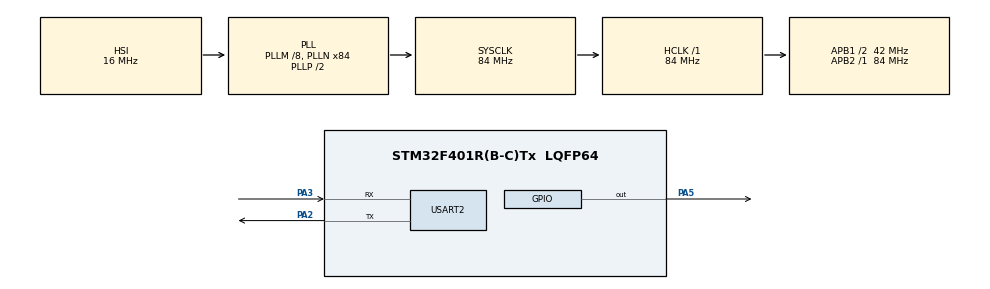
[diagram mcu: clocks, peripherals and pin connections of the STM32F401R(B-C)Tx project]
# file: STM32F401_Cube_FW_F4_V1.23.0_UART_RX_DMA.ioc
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Dma.Request0=USART2_TX
Dma.Request1=USART2_RX
Dma.USART2_RX.1.Direction=DMA_PERIPH_TO_MEMORY
Dma.USART2_RX.1.FIFOMode=DMA_FIFOMODE_DISABLE
Dma.USART2_RX.1.Instance=DMA1_Stream5
Dma.USART2_RX.1.MemDataAlignment=DMA_MDATAALIGN_BYTE
Dma.USART2_RX.1.MemInc=DMA_MINC_ENABLE
Dma.USART2_RX.1.Mode=DMA_CIRCULAR
Dma.USART2_RX.1.PeriphDataAlignment=DMA_PDATAALIGN_BYTE
Dma.USART2_RX.1.PeriphInc=DMA_PINC_DISABLE
Dma.USART2_RX.1.Priority=DMA_PRIORITY_LOW
Dma.USART2_TX.0.Direction=DMA_MEMORY_TO_PERIPH
Dma.USART2_TX.0.FIFOMode=DMA_FIFOMODE_DISABLE
Dma.USART2_TX.0.Instance=DMA1_Stream6
Dma.USART2_TX.0.MemDataAlignment=DMA_MDATAALIGN_BYTE
Dma.USART2_TX.0.MemInc=DMA_MINC_ENABLE
Dma.USART2_TX.0.Mode=DMA_NORMAL
Dma.USART2_TX.0.PeriphDataAlignment=DMA_PDATAALIGN_BYTE
Dma.USART2_TX.0.PeriphInc=DMA_PINC_DISABLE
Dma.USART2_TX.0.Priority=DMA_PRIORITY_LOW
Mcu.Family=STM32F4
Mcu.Name=STM32F401R(B-C)Tx
Mcu.Package=LQFP64
Mcu.UserConstants=SYSCLK,84000000;TIMERCLK,1000000;TIMERFREQ,1000
NVIC.DMA1_Stream5_IRQn=true\:0\:0\:false\:false\:true\:false\:true
NVIC.DMA1_Stream6_IRQn=true\:0\:0\:false\:false\:true\:false\:true
NVIC.PriorityGroup=NVIC_PRIORITYGROUP_4
NVIC.TIM1_TRG_COM_TIM11_IRQn=true\:0\:0\:false\:false\:true\:true\:true
NVIC.USART2_IRQn=true\:0\:0\:false\:false\:true\:true\:true
PA13.Mode=Serial_Wire
PA13.Signal=SYS_JTMS-SWDIO
PA14.Mode=Serial_Wire
PA14.Signal=SYS_JTCK-SWCLK
PA2.Mode=Asynchronous
PA2.Signal=USART2_TX
PA3.Mode=Asynchronous
PA3.Signal=USART2_RX
PA5.Signal=GPIO_Output
ProjectManager.HeapSize=0x200
ProjectManager.StackSize=0x400
ProjectManager.TargetToolchain=MDK-ARM V5
RCC.48MHZClocksFreq_Value=42000000
RCC.AHBFreq_Value=84000000
RCC.APB1CLKDivider=RCC_HCLK_DIV2
RCC.APB1Freq_Value=42000000
RCC.APB1TimFreq_Value=84000000
RCC.APB2Freq_Value=84000000
RCC.APB2TimFreq_Value=84000000
RCC.CortexFreq_Value=84000000
RCC.HCLKFreq_Value=84000000
RCC.HSE_VALUE=25000000
RCC.HSI_VALUE=16000000
RCC.LSE_VALUE=32768
RCC.PLLM=8
RCC.PLLN=84
RCC.SYSCLKFreq_VALUE=84000000
RCC.SYSCLKSource=RCC_SYSCLKSOURCE_PLLCLK
RCC.VCOOutputFreq_Value=168000000
TIM11.Period=TIMERCLK/TIMERFREQ-1
TIM11.Prescaler=SYSCLK/TIMERCLK-1
USART2.VirtualMode=VM_ASYNC
VP_TIM11_VS_ClockSourceINT.Mode=Enable_Timer
board=custom

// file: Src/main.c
/* USER CODE BEGIN Header */
/**
  ******************************************************************************
  * @file           : main.c
  * @brief          : Main program body
  ******************************************************************************
  * @attention
  *
  * <h2><center>&copy; Copyright (c) 2019 STMicroelectronics.
  * All rights reserved.</center></h2>
  *
  * This software component is licensed by ST under BSD 3-Clause license,
  * the "License"; You may not use this file except in compliance with the
  * License. You may obtain a copy of the License at:
  *                        opensource.org/licenses/BSD-3-Clause
  *
  ******************************************************************************
  */
/* USER CODE END Header */

#include "main.h"

/* USER CODE BEGIN PM */
#define RX_DMA_LEN						(256)
#define ARRAY_LEN(x)            			(sizeof(x) / sizeof((x)[0]))

/* USER CODE END PM */

TIM_HandleTypeDef htim11;

UART_HandleTypeDef huart2;
DMA_HandleTypeDef hdma_usart2_tx;
DMA_HandleTypeDef hdma_usart2_rx;

/* USER CODE BEGIN PV */

uint8_t aRxDMABuffer[RX_DMA_LEN] = {0};

/* USER CODE END PV */

void SystemClock_Config(void);
static void MX_GPIO_Init(void);
static void MX_DMA_Init(void);
static void MX_TIM11_Init(void);
static void MX_USART2_UART_Init(void);
/* USER CODE BEGIN PFP */

#ifdef __GNUC__
/* With GCC/RAISONANCE, small printf (option LD Linker->Libraries->Small printf
 set to 'Yes') calls __io_putchar() */
#define PUTCHAR_PROTOTYPE int __io_putchar(int ch)
#else
#define PUTCHAR_PROTOTYPE int fputc(int ch, FILE *f)
#endif /* __GNUC__ */

/**
  * @brief  Retargets the C library printf function to the USART.
  * @param  None
  * @retval None
  */

PUTCHAR_PROTOTYPE
{
	/* Place your implementation of fputc here */
	/* e.g. write a character to the EVAL_COM1 and Loop until the end of transmission */
	HAL_UART_Transmit(&huart2, (uint8_t *)&ch, 1, 0xFFFF);

	return ch;
}

/* USER CODE END PFP */

/* USER CODE BEGIN 0 */

void customIRQ_UART_RxIDLE(void)
{
	//https://github.com/MaJerle/STM32_USART_DMA_RX/blob/master/projects/idle_line_irq_F4/Src/main.c

	static uint16_t OldLength = 0;
	uint16_t RxLength = 0;

	if(__HAL_UART_GET_IT_SOURCE(&huart2, UART_IT_IDLE)  && __HAL_UART_GET_FLAG(&huart2, UART_FLAG_IDLE))
	{
		__HAL_UART_CLEAR_IDLEFLAG(&huart2);

		RxLength = ARRAY_LEN(aRxDMABuffer) - (__HAL_DMA_GET_COUNTER(&hdma_usart2_rx));	//calculate how many data in DMA buffer
//		printf("RX length : 0x%2X \r\n" , RxLength);

		if (RxLength != OldLength)
		{
			if (RxLength > OldLength)
			{
				HAL_UART_Transmit_DMA(&huart2,&aRxDMABuffer[OldLength],RxLength-OldLength);
			}
			else
			{
				HAL_UART_Transmit_DMA(&huart2,&aRxDMABuffer[OldLength],ARRAY_LEN(aRxDMABuffer)-OldLength);
				if (RxLength)
				{
					HAL_UART_Transmit_DMA(&huart2,&aRxDMABuffer[0],RxLength);
				}
			}
		}

		OldLength = (OldLength == ARRAY_LEN(aRxDMABuffer))?(0):(RxLength);
	}
}

void HAL_TIM_PeriodElapsedCallback(TIM_HandleTypeDef *htim)
{
	static uint32_t cnt1 = 0;
	static uint32_t i = 0;

	if (htim->Instance == TIM11)
	{
		if (cnt1++ >= (1*1000))	// per 1 s
		{
			cnt1 = 0;
			printf("%s : %4d\r\n",__FUNCTION__,i++);

		}
	}
}

/* USER CODE END 0 */

int main(void)
{

  /* MCU Configuration--------------------------------------------------------*/

  /* Reset of all peripherals, Initializes the Flash interface and the Systick. */
  HAL_Init();

  /* Configure the system clock */
  SystemClock_Config();

  /* Initialize all configured peripherals */
  MX_GPIO_Init();
  MX_DMA_Init();
  MX_TIM11_Init();
  MX_USART2_UART_Init();

  /* Infinite loop */
  while (1)
  {

    /* USER CODE BEGIN 3 */

	HAL_Delay(1000);
	HAL_GPIO_TogglePin(GPIOA, GPIO_PIN_5);
  }
  /* USER CODE END 3 */
}

void SystemClock_Config(void)
{
  RCC_OscInitTypeDef RCC_OscInitStruct = {0};
  RCC_ClkInitTypeDef RCC_ClkInitStruct = {0};

  /** Configure the main internal regulator output voltage
  */
  __HAL_RCC_PWR_CLK_ENABLE();
  __HAL_PWR_VOLTAGESCALING_CONFIG(PWR_REGULATOR_VOLTAGE_SCALE2);
  /** Initializes the CPU, AHB and APB busses clocks
  */
  RCC_OscInitStruct.OscillatorType = RCC_OSCILLATORTYPE_HSI;
  RCC_OscInitStruct.HSIState = RCC_HSI_ON;
  RCC_OscInitStruct.HSICalibrationValue = RCC_HSICALIBRATION_DEFAULT;
  RCC_OscInitStruct.PLL.PLLState = RCC_PLL_ON;
  RCC_OscInitStruct.PLL.PLLSource = RCC_PLLSOURCE_HSI;
  RCC_OscInitStruct.PLL.PLLM = 8;
  RCC_OscInitStruct.PLL.PLLN = 84;
  RCC_OscInitStruct.PLL.PLLP = RCC_PLLP_DIV2;
  RCC_OscInitStruct.PLL.PLLQ = 4;
  if (HAL_RCC_OscConfig(&RCC_OscInitStruct) != HAL_OK)
  {
    Error_Handler();
  }
  /** Initializes the CPU, AHB and APB busses clocks
  */
  RCC_ClkInitStruct.ClockType = RCC_CLOCKTYPE_HCLK|RCC_CLOCKTYPE_SYSCLK
                              |RCC_CLOCKTYPE_PCLK1|RCC_CLOCKTYPE_PCLK2;
  RCC_ClkInitStruct.SYSCLKSource = RCC_SYSCLKSOURCE_PLLCLK;
  RCC_ClkInitStruct.AHBCLKDivider = RCC_SYSCLK_DIV1;
  RCC_ClkInitStruct.APB1CLKDivider = RCC_HCLK_DIV2;
  RCC_ClkInitStruct.APB2CLKDivider = RCC_HCLK_DIV1;

  if (HAL_RCC_ClockConfig(&RCC_ClkInitStruct, FLASH_LATENCY_2) != HAL_OK)
  {
    Error_Handler();
  }
}

static void MX_TIM11_Init(void)
{

  htim11.Instance = TIM11;
  htim11.Init.Prescaler = SYSCLK/TIMERCLK-1;
  htim11.Init.CounterMode = TIM_COUNTERMODE_UP;
  htim11.Init.Period = TIMERCLK/TIMERFREQ-1;
  htim11.Init.ClockDivision = TIM_CLOCKDIVISION_DIV1;
  htim11.Init.AutoReloadPreload = TIM_AUTORELOAD_PRELOAD_DISABLE;
  if (HAL_TIM_Base_Init(&htim11) != HAL_OK)
  {
    Error_Handler();
  }
  /* USER CODE BEGIN TIM11_Init 2 */
  if (HAL_TIM_Base_Start_IT(&htim11) != HAL_OK)
  {
    /* Starting Error */
    Error_Handler();
  }
  /* USER CODE END TIM11_Init 2 */

}

static void MX_USART2_UART_Init(void)
{

  huart2.Instance = USART2;
  huart2.Init.BaudRate = 115200;
  huart2.Init.WordLength = UART_WORDLENGTH_8B;
  huart2.Init.StopBits = UART_STOPBITS_1;
  huart2.Init.Parity = UART_PARITY_NONE;
  huart2.Init.Mode = UART_MODE_TX_RX;
  huart2.Init.HwFlowCtl = UART_HWCONTROL_NONE;
  huart2.Init.OverSampling = UART_OVERSAMPLING_16;
  if (HAL_UART_Init(&huart2) != HAL_OK)
  {
    Error_Handler();
  }
  /* USER CODE BEGIN USART2_Init 2 */

	printf("HAL_RCC_GetSysClockFreq = %d\r\n",HAL_RCC_GetSysClockFreq());
 	printf("HAL_RCC_GetHCLKFreq = %d\r\n",HAL_RCC_GetHCLKFreq());
	printf("HAL_RCC_GetPCLK1Freq = %d\r\n",HAL_RCC_GetPCLK1Freq());
	printf("HAL_RCC_GetPCLK2Freq = %d\r\n",HAL_RCC_GetPCLK2Freq());

	__HAL_UART_ENABLE_IT(&huart2,UART_IT_IDLE);

	HAL_UART_Receive_DMA(&huart2,aRxDMABuffer,ARRAY_LEN(aRxDMABuffer));

  /* USER CODE END USART2_Init 2 */

}

static void MX_DMA_Init(void)
{
  /* DMA controller clock enable */
  __HAL_RCC_DMA1_CLK_ENABLE();

  /* DMA interrupt init */
  /* DMA1_Stream5_IRQn interrupt configuration */
  HAL_NVIC_SetPriority(DMA1_Stream5_IRQn, 0, 0);
  HAL_NVIC_EnableIRQ(DMA1_Stream5_IRQn);
  /* DMA1_Stream6_IRQn interrupt configuration */
  HAL_NVIC_SetPriority(DMA1_Stream6_IRQn, 0, 0);
  HAL_NVIC_EnableIRQ(DMA1_Stream6_IRQn);

}

static void MX_GPIO_Init(void)
{
  GPIO_InitTypeDef GPIO_InitStruct = {0};

  /* GPIO Ports Clock Enable */
  __HAL_RCC_GPIOA_CLK_ENABLE();

  /*Configure GPIO pin Output Level */
  HAL_GPIO_WritePin(GPIOA, GPIO_PIN_5, GPIO_PIN_RESET);

  /*Configure GPIO pin : PA5 */
  GPIO_InitStruct.Pin = GPIO_PIN_5;
  GPIO_InitStruct.Mode = GPIO_MODE_OUTPUT_PP;
  GPIO_InitStruct.Pull = GPIO_NOPULL;
  GPIO_InitStruct.Speed = GPIO_SPEED_FREQ_LOW;
  HAL_GPIO_Init(GPIOA, &GPIO_InitStruct);

}

void Error_Handler(void)
{
}

/************************ (C) COPYRIGHT STMicroelectronics *****END OF FILE****/
